# AES_1.0 register map
Vendor: Texas Instruments
Peripheral module from a debugger description file (folder mspm0g1x0x_g3x0x).
Registers are 32-bit, read-write, no defined reset value unless marked. A register's access mark holds for its fields unless they carry their own. Offsets are as the file gives them; lines under a group give offsets from that group; [hi:lo] are bit positions; {n}, {i} and the like mark numbered series; 'fields as' and 'values as' point back to an identical list; <NAME> marks a mode.

## AES
0x800 AES_GPRCM group
  0x00 AES_PWREN — Power enable
    [0] ENABLE — Enable the power
      0=DISABLE (Disable Power); 1=ENABLE (Enable Power)
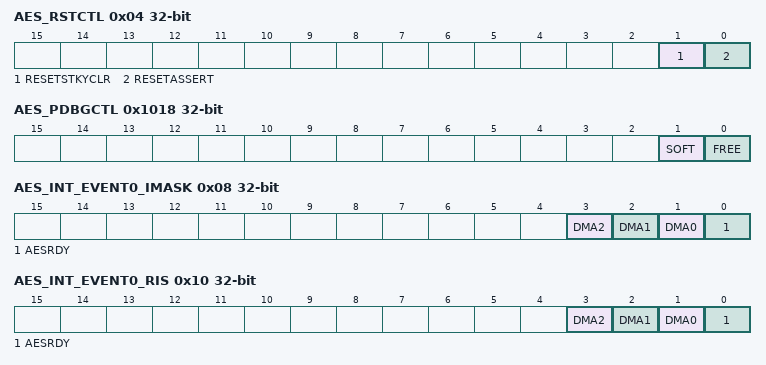
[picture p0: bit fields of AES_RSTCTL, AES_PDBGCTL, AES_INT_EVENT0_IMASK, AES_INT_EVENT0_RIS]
  0x04 AES_RSTCTL — Reset Control
    [1] RESETSTKYCLR — Clear the RESETSTKY bit in the STAT register
      0=NOP (Writing 0 has no effect); 1=CLR (Clear reset sticky bit)
    [0] RESETASSERT — Assert reset to the peripheral
      0=NOP (Writing 0 has no effect); 1=ASSERT (Assert reset)
  0x14 AES_STAT ro — Status Register
    [16] RESETSTKY — This bit indicates, if the peripheral was reset, since this bit was cleared by RESETSTKYCLR in the RSTCTL register
      0=NORES (The peripheral has not been reset since this bit was last cleared by RESETSTKYCLR in the RSTCTL register); 1=RESET (The peripheral was reset since the last bit clear)
0x1018 AES_PDBGCTL — Peripheral Debug Control
  [1] SOFT — Soft halt boundary control. This function is only available, if [FREE] is set to 'STOP'
    0=IMMEDIATE (The peripheral will halt immediately, even if the resultant state will result in corruption if the system is restarted); 1=DELAYED (The peripheral blocks the debug freeze until it has reached a boundary where it can resume without corruption)
  [0] FREE — Free run control
    0=STOP (The peripheral freezes functionality while the Core Halted input is asserted and resumes when it is deasserted.); 1=RUN (The peripheral ignores the state of the Core Halted input)
0x1020 AES_INT_EVENT0 group
  0x00 AES_INT_EVENT0_IIDX ro — Interrupt Index Register
    [7:0] STAT — Interrupt index status
      0=NO_INTR (No interrupt pending); 1=AESRDY (AES ready interrupt, set when the selected AES operation was completed and the result can be read from AESADOUT); 2=DMA0 (AES trigger 0 DMA); 3=DMA1 (AES trigger 1 DMA); 4=DMA2 (AES trigger 2 DMA)
  0x08 AES_INT_EVENT0_IMASK — Interrupt mask
    [all] fields
      0=CLR (Clear Interrupt Mask); 1=SET (Set Interrrupt Mask)
    [3] DMA2 — DMA2 event mask.
    [2] DMA1 — DMA1 event mask.
    [1] DMA0 — DMA0 event mask.
    [0] AESRDY — AES ready interrupt, set when the selected AES operation was completed and the result can be read from AESADOUT.
  0x10 AES_INT_EVENT0_RIS — Raw interrupt status
    [all] fields
      0=CLR (Interrupt did not occur); 1=SET (Interrupt occured)
    [3] DMA2 — DMA2 event
    [2] DMA1 — DMA1 event
    [1] DMA0 — DMA0 event
    [0] AESRDY — AES ready interrupt, set when the selected AES operation was completed and the result can be read from AESADOUT.
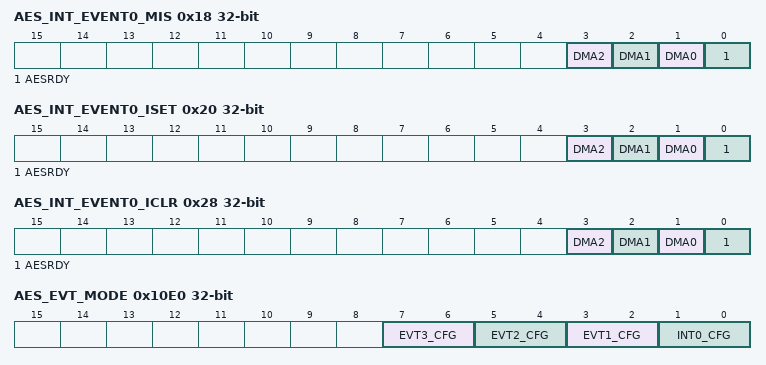
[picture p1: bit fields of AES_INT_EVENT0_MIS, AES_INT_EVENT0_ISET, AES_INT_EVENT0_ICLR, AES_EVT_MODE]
  0x18 AES_INT_EVENT0_MIS — Masked interrupt status
    fields as AES_INT_EVENT0.AES_INT_EVENT0_RIS
  0x20 AES_INT_EVENT0_ISET — Interrupt set
    [all] fields
      0=NO_EFFECT (Writing 0 has no effect); 1=SET (Set Interrupt)
    [3] DMA2
    [2] DMA1
    [1] DMA0
    [0] AESRDY — AES ready interrupt, set when the selected AES operation was completed and the result can be read from AESADOUT.
  0x28 AES_INT_EVENT0_ICLR — Interrupt clear
    [all] fields
      0=NO_EFFECT (Writing 0 has no effect); 1=CLR (Clear Interrupt)
    [3] DMA2
    [2] DMA1
    [1] DMA0
    [0] AESRDY — AES ready interrupt, set when the selected AES operation was completed and the result can be read from AESADOUT.
0x1050 AES_INT_EVENT1 group
  0x00 AES_INT_EVENT1_IIDX ro — Interrupt Index Register
    [7:0] STAT — Interrupt index status
      0=NO_INTR (No interrupt pending); 2=DMA0 (AES trigger 0 DMA)
  0x08 AES_INT_EVENT1_IMASK — Interrupt mask
    [1] DMA0 — DMA0 event mask.
      0=CLR (Clear Interrupt Mask); 1=SET (Set Interrrupt Mask)
  0x10 AES_INT_EVENT1_RIS — Raw interrupt status
    [1] DMA0 — DMA0 event
      0=CLR (Interrupt did not occur); 1=SET (Interrupt occured)
  0x18 AES_INT_EVENT1_MIS — Masked interrupt status
    fields as AES_INT_EVENT1.AES_INT_EVENT1_RIS
  0x20 AES_INT_EVENT1_ISET — Interrupt set
    [1] DMA0
      0=NO_EFFECT (Writing 0 has no effect); 1=SET (Set Interrupt)
  0x28 AES_INT_EVENT1_ICLR — Interrupt clear
    [1] DMA0 — DMA0 event
      values as the fields of AES_INT_EVENT0.AES_INT_EVENT0_ICLR
0x1080 AES_INT_EVENT2 group
  0x00 AES_INT_EVENT2_IIDX ro — Interrupt Index Register
    [7:0] STAT — Interrupt index status
      0=NO_INTR (No interrupt pending); 3=DMA1 (AES trigger 1 DMA)
  0x08 AES_INT_EVENT2_IMASK — Interrupt mask
    [2] DMA1 — DMA1 event mask.
      0=CLR (Clear Interrupt Mask); 1=SET (Set Interrrupt Mask)
  0x10 AES_INT_EVENT2_RIS — Raw interrupt status
    [2] DMA1 — DMA1 event
      0=CLR (Interrupt did not occur); 1=SET (Interrupt occured)
  0x18 AES_INT_EVENT2_MIS — Masked interrupt status
    fields as AES_INT_EVENT2.AES_INT_EVENT2_RIS
  0x20 AES_INT_EVENT2_ISET — Interrupt set
    [2] DMA1 — DMA1 event
      0=NO_EFFECT (Writing 0 has no effect); 1=SET (Set Interrupt)
  0x28 AES_INT_EVENT2_ICLR — Interrupt clear
    [2] DMA1 — DMA1 event
      values as the fields of AES_INT_EVENT0.AES_INT_EVENT0_ICLR
0x10B0 AES_INT_EVENT3 group
  0x00 AES_INT_EVENT3_IIDX ro — Interrupt Index Register
    [7:0] STAT — Interrupt index status
      0=NO_INTR (No interrupt pending); 4=DMA2 (AES trigger 2 DMA)
  0x08 AES_INT_EVENT3_IMASK — Interrupt mask
    [3] DMA2 — DMA2 event mask.
      0=CLR (Clear Interrupt Mask); 1=SET (Set Interrrupt Mask)
  0x10 AES_INT_EVENT3_RIS — Raw interrupt status
    [3] DMA2 — DMA2 event
      0=CLR (Interrupt did not occur); 1=SET (Interrupt occured)
  0x18 AES_INT_EVENT3_MIS — Masked interrupt status
    fields as AES_INT_EVENT3.AES_INT_EVENT3_RIS
  0x20 AES_INT_EVENT3_ISET — Interrupt set
    [3] DMA2 — DMA2 event
      0=NO_EFFECT (Writing 0 has no effect); 1=SET (Set Interrupt)
  0x28 AES_INT_EVENT3_ICLR — Interrupt clear
    [3] DMA2 — DMA2 event
      values as the fields of AES_INT_EVENT0.AES_INT_EVENT0_ICLR
0x10E0 AES_EVT_MODE ro — Event Mode
  [all] fields
    0=DISABLE (The interrupt or event line is disabled.); 1=SOFTWARE (The interrupt or event line is in software mode. Software must clear the RIS.); 2=HARDWARE (The interrupt or event line is in hardware mode. The hardware (another module) clears automatically the associated RIS flag.)
  [7:6] EVT3_CFG — Event line mode select for event corresponding to [IPSTANDARD.INT_EVENT2]
  [5:4] EVT2_CFG — Event line mode select for event corresponding to [IPSTANDARD.INT_EVENT2]
  [3:2] EVT1_CFG — Event line mode select for event corresponding to [IPSTANDARD.INT_EVENT1]
  [1:0] INT0_CFG — Event line mode select for event corresponding to [IPSTANDARD.INT_EVENT0]
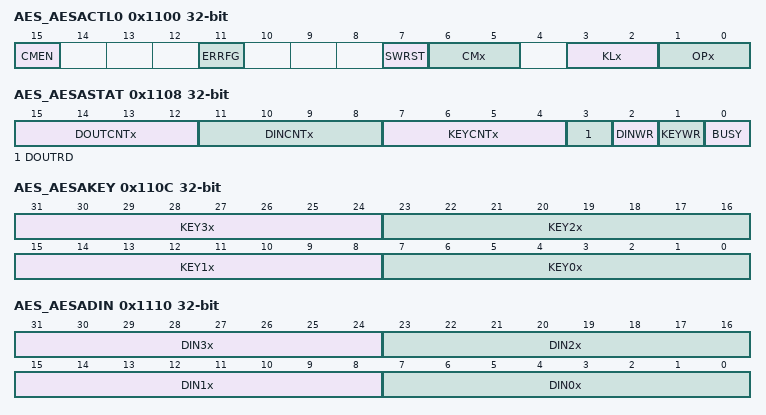
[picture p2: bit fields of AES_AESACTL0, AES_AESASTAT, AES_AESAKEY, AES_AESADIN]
0x1100 AES_AESACTL0 — AES accelerator control register 0
  [15] CMEN — AESCMEN enables the support of the cipher modes ECB, CBC, OFB and CFB together with the DMA. Writes are ignored when AESCMEN = 1 and AESBLKCNTx > 0. 0 = No DMA triggers are generated. 1 = DMA cipher mode support operation is enabled and the corresponding DMA triggers are generated.
    0=DISABLE (No DMA triggers are generated.); 1=ENABLE (DMA cipher mode support operation is enabled and the corresponding DMA triggers are generated.)
  [11] ERRFG — AES error flag. AESAKEY or AESADIN were written while an AES operation was in progress. The bit must be cleared by software. 0b = No error 1b = Error occurred
    0=NOERR (No error); 1=ERR (Error occurred)
  [7] SWRST — AES software reset. Immediately resets the complete AES accelerator module even when busy except for the AESRDYIE, the AESKLx and the AESOPx bits. It also clears the (internal) state memory. The AESSWRST bit is automatically reset and is always read as zero. 0b = No reset 1b = Reset AES accelerator module
    0=NORST (No reset.); 1=RST (Reset AES accelerator module.)
  [6:5] CMx — AES cipher mode select. These bits are ignored for AESCMEN = 0. Writes are ignored when AESCMEN = 1 and AESBLKCNTx > 0. 00b = ECB 01b = CBC 10b = OFB 11b = CFB
    0=ECB; 1=CBC; 2=OFB; 3=CFB
  [3:2] KLx — AES key length. These bits define which of the 1 AES standards is performed. The AESKLx bits are not reset by AESSWRST = 1. Writes are ignored when AESCMEN = 1 and AESBLKCNTx > 0.
    0=AES128 (The key size is 128 bit.); 2=AES256 (The key size is 256 bit.)
  [1:0] OPx — AES operation. The AESOPx bits are not reset by AESSWRST = 1. Writes are ignored when AESCMEN = 1 and AESBLKCNTx > 0. 00b = Encryption. 01b = Decryption. The provided key is the same key used for encryption. 10b = Generate first round key required for decryption. 11b = Decryption. The provided key is the first round key required for decryption.
    0=OP0 (Encryption); 1=OP1 (Decryption. The provided key is the same key used for encryption.); 2=OP2 (Generate first round key required for decryption.); 3=OP3 (Decryption. The provided key is the first round key required for decryption.)
0x1104 AES_AESACTL1 — AES accelerator control register 1
  [7:0] BLKCNTx — Cipher Block Counter. Number of blocks to be encrypted or decrypted with block cipher modes enabled (AESCMEN = 1). Ignored if AESCMEN = 0. The block counter decrements with each performed encryption or decryption. Writes are ignored when AESCMEN = 1 and AESBLKCNTx > 0.
    0=MINNUM (Smallest value); 255=ENABLE (Highest possible value)
0x1108 AES_AESASTAT access per field — aes accelerator status register
  [15:12] DOUTCNTx ro — Bytes read from AESADOUT. Reset when AESDOUTRD is reset. If AESDOUTCNTx = 0 and AESDOUTRD = 0, no bytes were read. If AESDOUTCNTx = 0 and AESDOUTRD = 1, all bytes were read.
    0=MINNUM (Smallest possible value); 15=MAXNUM (Highest possible value)
  [11:8] DINCNTx ro — Bytes written to AESADIN, AESAXDIN or AESAXIN. Reset when AESDINWR is reset. If AESDINCNTx = 0 and AESDINWR = 0, no bytes were written. If AESDINCNTx = 0 and AESDINWR = 1, all bytes were written.
    values as DOUTCNTx
  [7:4] KEYCNTx ro — Bytes written to AESAKEY when AESKLx = 00, half-words written to AESAKEY if AESKLx = b10. Reset when AESKEYWR is reset. If AESKEYCNTx = 0 and AESKEYWR = 0, no bytes were written. If AESKEYCNTx = 0 and AESKEYWR = 1, all bytes were written.
    values as DOUTCNTx
  [3] DOUTRD ro — All 16 bytes read from AESADOUT. AESDOUTRD is reset by PUC, AESSWRST, an error condition, changing AESOPx, changing AESKLx, when the AES accelerator is busy, and when the output data is read again. 0 = Not all bytes read 1 = All bytes read
    0=NALL (Not all bytes read); 1=ALL (All bytes read)
  [2] DINWR rw — All 16 bytes written to AESADIN, AESAXDIN or AESAXIN. Changing its state by software also resets the AESDINCNTx bits. AESDINWR is reset by PUC, AESSWRST, an error condition, changing AESOPx, changing AESKLx, the start to (over)write the data, and when the AES accelerator is busy. Because it is reset when AESOPx or AESKLx is changed it can be set by software again to indicate that the current data is still valid. 0 = Not all bytes written 1 = All bytes written
    0=NALL (Not all bytes written); 1=ALL (All bytes written)
  [1] KEYWR rw — All bytes written to AESAKEY. This bit can be modified by software but it must not be reset by software (10) if AESCMEN=1. Changing its state by software also resets the AESKEYCNTx bits. AESKEYWR is reset by PUC, AESSWRST, an error condition, changing AESOPx, changing AESKLx, and the start to (over)write a new key. Because it is reset when AESOPx is changed it can be set by software again to indicate that the loaded key is still valid.
    0=NALL (Not all bytes written); 1=ALL (All bytes written)
  [0] BUSY ro — AES accelerator module busy; encryption, decryption, or key generation in progress. 0 = Not busy 1 = Busy
    0=IDLE (Not busy); 1=BUSY
0x110C AES_AESAKEY — aes accelerator key register
  [all] fields
    0=MINNUM (Smallest possible value); 255=MAXNUM (Highest possible value)
  [31:24] KEY3x — AES key byte n+3 when AESAKEY is written as word. Do not use these bits for byte access. Do not mix word and byte access. Always reads as zero. The key is reset by PUC or by AESSWRST = 1.
  [23:16] KEY2x — AES key byte n+2 when AESAKEY is written as word. Do not use these bits for byte access. Do not mix word and byte access. Always reads as zero. The key is reset by PUC or by AESSWRST = 1.
  [15:8] KEY1x — AES key byte n+1 when AESAKEY is written as word. Do not use these bits for byte access. Do not mix word and byte access. Always reads as zero. The key is reset by PUC or by AESSWRST = 1.
  [7:0] KEY0x — AES key byte n when AESAKEY is written as word. AES next key byte when AESAKEY is written as byte. Do not mix word and byte access. Always reads as zero. The key is reset by PUC or by AESSWRST = 1.
0x1110 AES_AESADIN — aes accelerator data in register
  [all] fields
    values as the fields of AES_AESAKEY
  [31:24] DIN3x — AES data in byte n+3 when AESADIN is written as word. Do not use these bits for byte access. Do not mix word and byte access. Always reads as zero.
  [23:16] DIN2x — AES data in byte n+2 when AESADIN is written as word. Do not use these bits for byte access. Do not mix word and byte access. Always reads as zero.
  [15:8] DIN1x — AES data in byte n+1 when AESADIN is written as word. Do not use these bits for byte access. Do not mix word and byte access. Always reads as zero.
  [7:0] DIN0x — AES data in byte n when AESADIN is written as word. AES next data in byte when AESADIN is written as byte. Do not mix word and byte access. Always reads as zero.
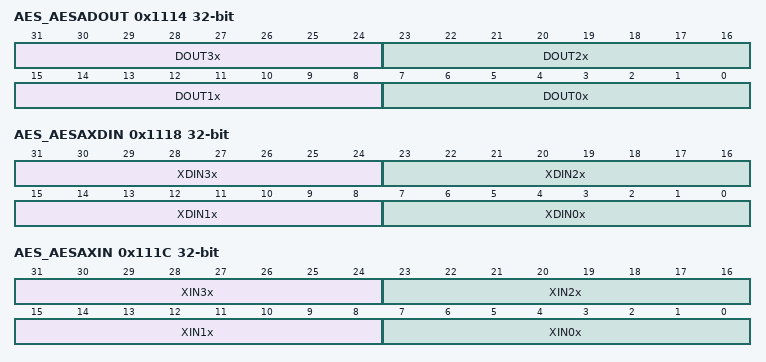
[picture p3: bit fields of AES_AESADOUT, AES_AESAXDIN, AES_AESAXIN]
0x1114 AES_AESADOUT ro — aes accelerator data out register
  [all] fields
    values as the fields of AES_AESAKEY
  [31:24] DOUT3x — AES data out byte n+3 when AESADOUT is read as word. Do not use these bits for byte access. Do not mix word and byte access.
  [23:16] DOUT2x — AES data out byte n+2 when AESADOUT is read as word. Do not use these bits for byte access. Do not mix word and byte access.
  [15:8] DOUT1x — AES data out byte n+1 when AESADOUT is read as word. Do not use these bits for byte access. Do not mix word and byte access.
  [7:0] DOUT0x — AES data out byte n when AESADOUT is read as word. AES next data out byte when AESADOUT is read as byte. Do not mix word and byte access.
0x1118 AES_AESAXDIN — aes accelerator xored data in register
  [all] fields
    values as the fields of AES_AESAKEY
  [31:24] XDIN3x — AES data in byte n+3 when AESAXDIN is written as word. Do not use these bits for byte access. Do not mix word and byte access. Always reads as zero.
  [23:16] XDIN2x — AES data in byte n+2 when AESAXDIN is written as word. Do not use these bits for byte access. Do not mix word and byte access. Always reads as zero.
  [15:8] XDIN1x — AES data in byte n+1 when AESAXDIN is written as word. Do not use these bits for byte access. Do not mix word and byte access. Always reads as zero.
  [7:0] XDIN0x — AES data in byte n when AESAXDIN is written as word. AES next data in byte when AESAXDIN is written as byte. Do not mix word and byte access. Always reads as zero.
0x111C AES_AESAXIN — aes accelerator xored data in register (no trigger)
  [all] fields
    values as the fields of AES_AESAKEY
  [31:24] XIN3x — AES data in byte n+3 when AESAXIN is written as word. Do not use these bits for byte access. Do not mix word and byte access. Always reads as zero.
  [23:16] XIN2x — AES data in byte n+2 when AESAXIN is written as word. Do not use these bits for byte access. Do not mix word and byte access. Always reads as zero.
  [15:8] XIN1x — AES data in byte n+1 when AESAXIN is written as word. Do not use these bits for byte access. Do not mix word and byte access. Always reads as zero.
  [7:0] XIN0x — AES data in byte n when AESAXIN is written as word. AES next data in byte when AESAXIN is written as byte. Do not mix word and byte access. Always reads as zero.
